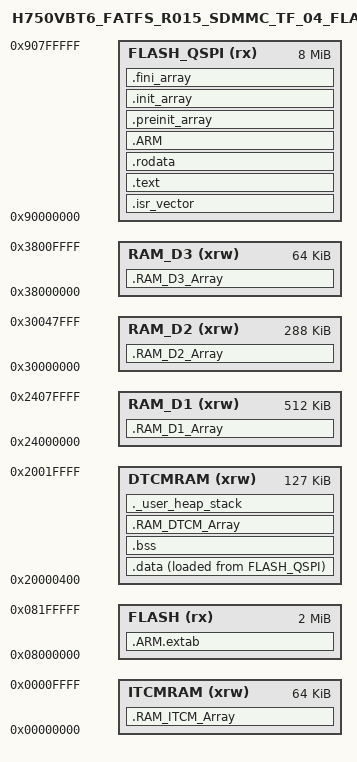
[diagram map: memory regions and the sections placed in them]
/*
******************************************************************************
**
**  File        : LinkerScript.ld
**
**  Author      : STM32CubeIDE
**
**  Abstract    : Linker script for STM32H7 series
**                128Kbytes FLASH and 1056Kbytes RAM
**
**                Set heap size, stack size and stack location according
**                to application requirements.
**
**                Set memory bank area and size if external memory is used.
**
**  Target      : STMicroelectronics STM32
**
**  Distribution: The file is distributed as is, without any warranty
**                of any kind.
**
*****************************************************************************
** @attention
**
** <h2><center>&copy; Copyright (c) 2021 STMicroelectronics.
** All rights reserved.</center></h2>
**
** This software component is licensed by ST under BSD 3-Clause license,
** the "License"; You may not use this file except in compliance with the
** License. You may obtain a copy of the License at:
**                        opensource.org/licenses/BSD-3-Clause
**
****************************************************************************
*/

/* Entry Point */
ENTRY(Reset_Handler)

/* Highest address of the user mode stack */
_estack = ORIGIN(DTCMRAM) + LENGTH(DTCMRAM);    /* end of RAM */
/* Generate a link error if heap and stack don't fit into RAM */
_Min_Heap_Size = 0x1000 ;      /* required amount of heap  */
_Min_Stack_Size = 0x1000 ; /* required amount of stack */

/* Specify the memory areas */
MEMORY
{
  FLASH (rx)     : ORIGIN = 0x08000000, LENGTH = 2048K
  FLASH_QSPI (rx) : ORIGIN = 0x90000000, LENGTH = 8M		/*8MB => 64Mb, W25Q64JV */
  DTCMRAM (xrw)  : ORIGIN = 0x20000400, LENGTH = 127K
  RAM_D1 (xrw)   : ORIGIN = 0x24000000, LENGTH = 512K
  RAM_D2 (xrw)   : ORIGIN = 0x30000000, LENGTH = 288K
  RAM_D3 (xrw)   : ORIGIN = 0x38000000, LENGTH = 64K
  ITCMRAM (xrw)  : ORIGIN = 0x00000000, LENGTH = 64K
}

/* Define output sections */
SECTIONS
{
  /* The startup code goes first into FLASH */
  .isr_vector :
  {
    . = ALIGN(4);
    KEEP(*(.isr_vector)) /* Startup code */
    . = ALIGN(4);
  } >FLASH_QSPI

  /* The program code and other data goes into FLASH */
  .text :
  {
    . = ALIGN(4);
    *(.text)           /* .text sections (code) */
    *(.text*)          /* .text* sections (code) */
    *(.glue_7)         /* glue arm to thumb code */
    *(.glue_7t)        /* glue thumb to arm code */
    *(.eh_frame)

    KEEP (*(.init))
    KEEP (*(.fini))

    . = ALIGN(4);
    _etext = .;        /* define a global symbols at end of code */
  } >FLASH_QSPI

  /* Constant data goes into FLASH */
  .rodata :
  {
    . = ALIGN(4);
    *(.rodata)         /* .rodata sections (constants, strings, etc.) */
    *(.rodata*)        /* .rodata* sections (constants, strings, etc.) */
    . = ALIGN(4);
  } >FLASH_QSPI

  .ARM.extab   : { *(.ARM.extab* .gnu.linkonce.armextab.*) } >FLASH
  .ARM : {
    __exidx_start = .;
    *(.ARM.exidx*)
    __exidx_end = .;
  } >FLASH_QSPI

  .preinit_array     :
  {
    PROVIDE_HIDDEN (__preinit_array_start = .);
    KEEP (*(.preinit_array*))
    PROVIDE_HIDDEN (__preinit_array_end = .);
  } >FLASH_QSPI

  .init_array :
  {
    PROVIDE_HIDDEN (__init_array_start = .);
    KEEP (*(SORT(.init_array.*)))
    KEEP (*(.init_array*))
    PROVIDE_HIDDEN (__init_array_end = .);
  } >FLASH_QSPI

  .fini_array :
  {
    PROVIDE_HIDDEN (__fini_array_start = .);
    KEEP (*(SORT(.fini_array.*)))
    KEEP (*(.fini_array*))
    PROVIDE_HIDDEN (__fini_array_end = .);
  } >FLASH_QSPI

  /* used by the startup to initialize data */
  _sidata = LOADADDR(.data);

  /* Initialized data sections goes into RAM, load LMA copy after code */
  .data :
  {
    . = ALIGN(4);
    _sdata = .;        /* create a global symbol at data start */
    *(.data)           /* .data sections */
    *(.data*)          /* .data* sections */
    *(.RamFunc)        /* .RamFunc sections */
    *(.RamFunc*)       /* .RamFunc* sections */

    . = ALIGN(4);
    _edata = .;        /* define a global symbol at data end */
  } >DTCMRAM AT> FLASH_QSPI

  /* Uninitialized data section */
  . = ALIGN(4);
  .bss :
  {
    /* This is used by the startup in order to initialize the .bss secion */
    _sbss = .;         /* define a global symbol at bss start */
    __bss_start__ = _sbss;
    *(.bss)
    *(.bss*)
    *(COMMON)

    . = ALIGN(4);
    _ebss = .;         /* define a global symbol at bss end */
    __bss_end__ = _ebss;
  } >DTCMRAM

  .RAM_DTCM_Array (NOLOAD):
  {
    *(.RAM_DTCM_Array)
  } >DTCMRAM
  
  .RAM_ITCM_Array (NOLOAD):
  {
    *(.RAM_ITCM_Array)
  } >ITCMRAM
  
  .RAM_D1_Array (NOLOAD):
  {
    *(.RAM_D1_Array)
  } >RAM_D1
  
  .RAM_D2_Array (NOLOAD):
  {
    *(.RAM_D2_Array)
  } >RAM_D2

  .RAM_D3_Array (NOLOAD):
  {
    *(.RAM_D3_Array)
  } >RAM_D3
  
  /* User_heap_stack section, used to check that there is enough RAM left */
  ._user_heap_stack :
  {
    . = ALIGN(8);
    PROVIDE ( end = . );
    PROVIDE ( _end = . );
    . = . + _Min_Heap_Size;
    . = . + _Min_Stack_Size;
    . = ALIGN(8);
  } >DTCMRAM

  /* Remove information from the standard libraries */
  /DISCARD/ :
  {
    libc.a ( * )
    libm.a ( * )
    libgcc.a ( * )
  }

  .ARM.attributes 0 : { *(.ARM.attributes) }
}


